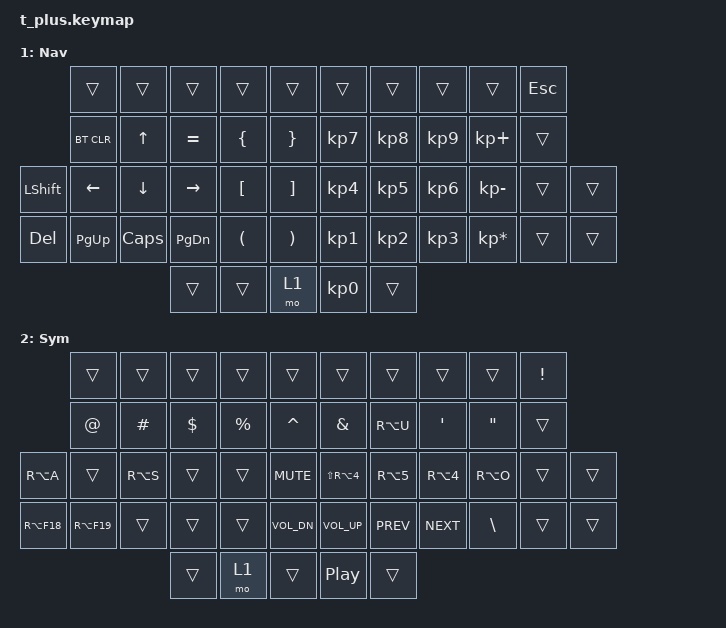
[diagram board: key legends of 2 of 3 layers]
//
//                                                        ▀▀▀▀▀     ▀▀▀▀▀          ▀▀█▀▀
//                                                        ▄▀▀▀▄  ▄  ▄▀▀▀▄  ▄  ▄▀▀▀▄  █  ▄▀▀▀▄
//                                                        █   █  █  █   █  █  █   █  █  █   █
//                                                         ▀▀▀   █   ▀▀▀   █   ▀▀▀   ▀   ▀▀▀
//                                                               █      ▄▄▄█▄▄▄    █   █
//                                                               ▀      █  █  █     █▄█
//                                                             ▀▀▀▀▀    █  █  █      ▀
//                                                                      ▀  ▀  ▀
//
// ▄▄▄▄▄▄▄▄▄▄▄▄▄▄▄▄▄▄▄▄▄▄▄▄▄▄▄▄▄▄▄▄▄▄▄▄▄▄▄▄▄▄▄▄▄▄▄▄▄▄▄▄▄▄▄▄▄▄▄▄▄▄▄▄▄▄▄▄▄▄▄▄▄▄▄▄▄▄▄▄▄▄▄▄▄▄▄▄▄▄▄▄▄▄▄▄▄▄▄▄▄▄▄▄▄▄▄▄▄▄▄▄▄▄▄▄▄▄▄▄▄▄▄▄▄▄▄▄▄▄▄▄▄▄▄▄▄▄▄▄▄▄▄▄▄▄▄▄▄

#include <behaviors.dtsi>
#include <dt-bindings/zmk/bt.h>
#include <dt-bindings/zmk/keys.h>

#define Base        0
#define Media       1
#define Nav         2
#define Mouse       3
#define Sym         4
#define Num         5
#define Button      6

&mt {
    quick-tap-ms = <100>;
    global-quick-tap;
    flavor = "tap-preferred";
    tapping-term-ms = <170>;
};

&lt {
    tapping-term-ms = <240>;
    flavor = "balanced";
    quick-tap-ms = <150>;
};

/ {
    behaviors {
        hm: homerow_mods {
            compatible = "zmk,behavior-hold-tap";
            label = "HOMEROW_MODS";
            #binding-cells = <2>;
            flavor = "tap-preferred";
            tapping-term-ms = <200>;
            quick-tap-ms = <125>;
            global-quick-tap;
            bindings = <&kp>, <&kp>;
        };
    };

    combos { compatible = "zmk,combos"; };

    keymap {
        compatible = "zmk,keymap";

        Base {
            label = "Base";
            bindings = <
              &kp N1      &kp N2      &kp N3         &kp N4        &kp N5       &kp N6   &kp N7       &kp N8       &kp N9      &kp N0
              &kp Q       &kp W       &kp E          &kp R         &kp T        &kp Y    &kp U        &kp I        &kp O       &kp P
&lt 1 ESCAPE  &hm LGUI A  &hm LALT S  &hm LCTRL D    &hm LSHIFT F  &kp G        &kp H    &hm RSHFT J  &hm RCTRL K  &hm RALT L  &hm RGUI SEMICOLON  &kp MINUS
&kp LSHIFT    &kp Z       &kp X       &kp C          &kp V         &kp B        &kp N    &kp M        &kp COMMA    &kp DOT     &kp SLASH           &lt 2 APOSTROPHE
                                      &mt LCTRL DEL  &lt 2 TAB     &kp SPACE    &kp RET  &lt 2 BSPC   &kp MINUS
            >;
        };

        Nav {
            label = "Nav";
            bindings = <
           &trans      &trans    &trans     &trans    &trans      &trans     &trans     &trans     &trans           &kp ESC
           &bt BT_CLR  &kp UP    &kp EQUAL  &kp LBRC  &kp RBRC    &kp KP_N7  &kp KP_N8  &kp KP_N9  &kp KP_PLUS      &trans
&kp LSHFT  &kp LEFT    &kp DOWN  &kp RIGHT  &kp LBKT  &kp RBKT    &kp KP_N4  &kp KP_N5  &kp KP_N6  &kp KP_MINUS     &trans   &trans
&kp DEL    &kp PG_UP   &kp CAPS  &kp PG_DN  &kp LPAR  &kp RPAR    &kp KP_N1  &kp KP_N2  &kp KP_N3  &kp KP_MULTIPLY  &trans   &trans
                                 &trans     &trans    &mo 1       &kp KP_N0  &trans
            >;
        };

        Sym {
            label = "Sym";
            bindings = <
             &trans       &trans     &trans    &trans     &trans          &trans          &trans      &trans      &trans     &kp EXCL
             &kp AT       &kp HASH   &kp DLLR  &kp PRCNT  &kp CARET       &kp AMPS        &kp RA(U)   &kp SQT     &kp DQT    &trans
&kp RA(A)    &trans       &kp RA(S)  &trans    &trans     &kp C_MUTE      &kp LS(RA(N4))  &kp RA(N5)  &kp RA(N4)  &kp RA(O)  &trans    &trans
&kp RA(F18)  &kp RA(F19)  &trans     &trans    &trans     &kp C_VOL_DN    &kp C_VOL_UP    &kp C_PREV  &kp C_NEXT  &kp BSLH   &trans    &trans
                                     &trans    &mo 1      &trans          &kp C_PP        &trans
            >;
        };
    };
};
